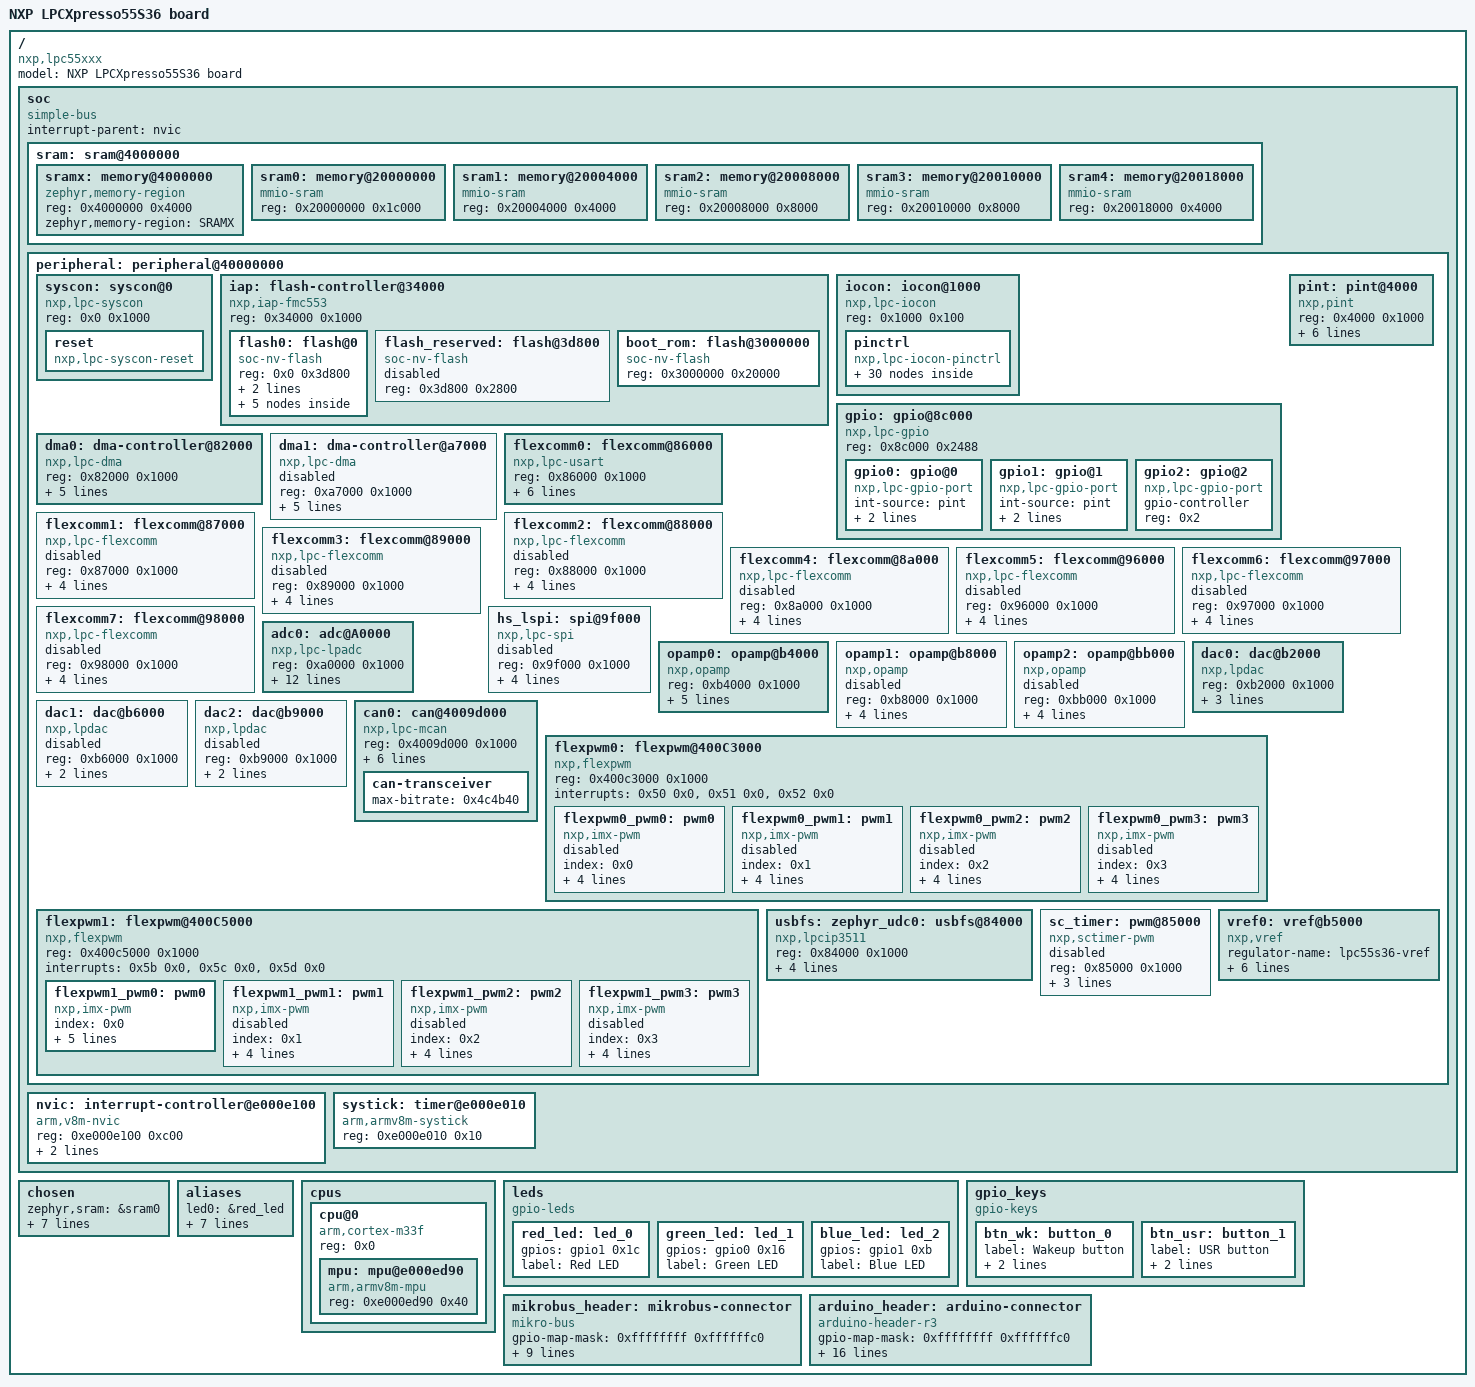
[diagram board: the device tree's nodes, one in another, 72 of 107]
/dts-v1/;

/* node '/' defined in zephyr/dts/arm/nxp/nxp_lpc55S36_ns.dtsi:7 */
/ {
	#address-cells = < 0x1 >;            /* in zephyr/dts/common/skeleton.dtsi:10 */
	#size-cells = < 0x1 >;               /* in zephyr/dts/common/skeleton.dtsi:11 */
	model = "NXP LPCXpresso55S36 board"; /* in zephyr/boards/nxp/lpcxpresso55s36/lpcxpresso55s36.dts:15 */
	compatible = "nxp,lpc55xxx",
	             "nxp,lpc";              /* in zephyr/boards/nxp/lpcxpresso55s36/lpcxpresso55s36.dts:16 */

	/* node '/soc' defined in zephyr/dts/arm/nxp/nxp_lpc55S36_ns.dtsi:8 */
	soc {
		#address-cells = < 0x1 >;     /* in zephyr/dts/arm/armv8-m.dtsi:7 */
		#size-cells = < 0x1 >;        /* in zephyr/dts/arm/armv8-m.dtsi:8 */
		compatible = "simple-bus";    /* in zephyr/dts/arm/armv8-m.dtsi:9 */
		interrupt-parent = < &nvic >; /* in zephyr/dts/arm/armv8-m.dtsi:10 */
		ranges;                       /* in zephyr/dts/arm/armv8-m.dtsi:11 */

		/* node '/soc/sram@4000000' defined in zephyr/dts/arm/nxp/nxp_lpc55S36_ns.dtsi:9 */
		sram: sram@4000000 {
			ranges = < 0x4000000 0x4000000 0x20000000 >; /* in zephyr/dts/arm/nxp/nxp_lpc55S36_ns.dtsi:10 */
			#address-cells = < 0x1 >;                    /* in zephyr/dts/arm/nxp/nxp_lpc55S3x_common.dtsi:37 */
			#size-cells = < 0x1 >;                       /* in zephyr/dts/arm/nxp/nxp_lpc55S3x_common.dtsi:38 */

			/* node '/soc/sram@4000000/memory@4000000' defined in zephyr/dts/arm/nxp/nxp_lpc55S3x_common.dtsi:44 */
			sramx: memory@4000000 {
				compatible = "zephyr,memory-region",
				             "mmio-sram";            /* in zephyr/dts/arm/nxp/nxp_lpc55S3x_common.dtsi:45 */
				reg = < 0x4000000 0x4000 >;          /* in zephyr/dts/arm/nxp/nxp_lpc55S3x_common.dtsi:46 */
				zephyr,memory-region = "SRAMX";      /* in zephyr/dts/arm/nxp/nxp_lpc55S3x_common.dtsi:47 */
			};

			/* node '/soc/sram@4000000/memory@20000000' defined in zephyr/dts/arm/nxp/nxp_lpc55S3x_common.dtsi:50 */
			sram0: memory@20000000 {
				compatible = "mmio-sram";     /* in zephyr/dts/arm/nxp/nxp_lpc55S36_ns.dtsi:26 */
				reg = < 0x20000000 0x1c000 >; /* in zephyr/dts/arm/nxp/nxp_lpc55S36_ns.dtsi:27 */
			};

			/* node '/soc/sram@4000000/memory@20004000' defined in zephyr/dts/arm/nxp/nxp_lpc55S3x_common.dtsi:55 */
			sram1: memory@20004000 {
				compatible = "mmio-sram";    /* in zephyr/dts/arm/nxp/nxp_lpc55S3x_common.dtsi:56 */
				reg = < 0x20004000 0x4000 >; /* in zephyr/dts/arm/nxp/nxp_lpc55S3x_common.dtsi:57 */
			};

			/* node '/soc/sram@4000000/memory@20008000' defined in zephyr/dts/arm/nxp/nxp_lpc55S3x_common.dtsi:60 */
			sram2: memory@20008000 {
				compatible = "mmio-sram";    /* in zephyr/dts/arm/nxp/nxp_lpc55S3x_common.dtsi:61 */
				reg = < 0x20008000 0x8000 >; /* in zephyr/dts/arm/nxp/nxp_lpc55S3x_common.dtsi:62 */
			};

			/* node '/soc/sram@4000000/memory@20010000' defined in zephyr/dts/arm/nxp/nxp_lpc55S3x_common.dtsi:65 */
			sram3: memory@20010000 {
				compatible = "mmio-sram";    /* in zephyr/dts/arm/nxp/nxp_lpc55S3x_common.dtsi:66 */
				reg = < 0x20010000 0x8000 >; /* in zephyr/dts/arm/nxp/nxp_lpc55S3x_common.dtsi:67 */
			};

			/* node '/soc/sram@4000000/memory@20018000' defined in zephyr/dts/arm/nxp/nxp_lpc55S3x_common.dtsi:70 */
			sram4: memory@20018000 {
				compatible = "mmio-sram";    /* in zephyr/dts/arm/nxp/nxp_lpc55S3x_common.dtsi:71 */
				reg = < 0x20018000 0x4000 >; /* in zephyr/dts/arm/nxp/nxp_lpc55S3x_common.dtsi:72 */
			};
		};

		/* node '/soc/peripheral@40000000' defined in zephyr/dts/arm/nxp/nxp_lpc55S36_ns.dtsi:13 */
		peripheral: peripheral@40000000 {
			ranges = < 0x0 0x40000000 0x10000000 >; /* in zephyr/dts/arm/nxp/nxp_lpc55S36_ns.dtsi:14 */
			#address-cells = < 0x1 >;               /* in zephyr/dts/arm/nxp/nxp_lpc55S3x_common.dtsi:77 */
			#size-cells = < 0x1 >;                  /* in zephyr/dts/arm/nxp/nxp_lpc55S3x_common.dtsi:78 */

			/* node '/soc/peripheral@40000000/syscon@0' defined in zephyr/dts/arm/nxp/nxp_lpc55S3x_common.dtsi:80 */
			syscon: syscon@0 {
				compatible = "nxp,lpc-syscon"; /* in zephyr/dts/arm/nxp/nxp_lpc55S3x_common.dtsi:81 */
				reg = < 0x0 0x1000 >;          /* in zephyr/dts/arm/nxp/nxp_lpc55S3x_common.dtsi:82 */
				#clock-cells = < 0x1 >;        /* in zephyr/dts/arm/nxp/nxp_lpc55S3x_common.dtsi:83 */
				phandle = < 0x2 >;             /* in zephyr/dts/arm/nxp/nxp_lpc55S3x_common.dtsi:199 */

				/* node '/soc/peripheral@40000000/syscon@0/reset' defined in zephyr/dts/arm/nxp/nxp_lpc55S3x_common.dtsi:85 */
				reset: reset {
					compatible = "nxp,lpc-syscon-reset"; /* in zephyr/dts/arm/nxp/nxp_lpc55S3x_common.dtsi:86 */
					#reset-cells = < 0x1 >;              /* in zephyr/dts/arm/nxp/nxp_lpc55S3x_common.dtsi:87 */
					phandle = < 0x3 >;                   /* in zephyr/dts/arm/nxp/nxp_lpc55S3x_common.dtsi:200 */
				};
			};

			/* node '/soc/peripheral@40000000/flash-controller@34000' defined in zephyr/dts/arm/nxp/nxp_lpc55S3x_common.dtsi:91 */
			iap: flash-controller@34000 {
				compatible = "nxp,iap-fmc553"; /* in zephyr/dts/arm/nxp/nxp_lpc55S3x_common.dtsi:92 */
				reg = < 0x34000 0x1000 >;      /* in zephyr/dts/arm/nxp/nxp_lpc55S3x_common.dtsi:93 */
				#address-cells = < 0x1 >;      /* in zephyr/dts/arm/nxp/nxp_lpc55S3x_common.dtsi:94 */
				#size-cells = < 0x1 >;         /* in zephyr/dts/arm/nxp/nxp_lpc55S3x_common.dtsi:95 */
				status = "okay";               /* in zephyr/dts/arm/nxp/nxp_lpc55S3x_common.dtsi:96 */

				/* node '/soc/peripheral@40000000/flash-controller@34000/flash@0' defined in zephyr/dts/arm/nxp/nxp_lpc55S3x_common.dtsi:98 */
				flash0: flash@0 {
					compatible = "soc-nv-flash";  /* in zephyr/dts/arm/nxp/nxp_lpc55S3x_common.dtsi:99 */
					reg = < 0x0 0x3d800 >;        /* in zephyr/dts/arm/nxp/nxp_lpc55S3x_common.dtsi:100 */
					erase-block-size = < 0x200 >; /* in zephyr/dts/arm/nxp/nxp_lpc55S3x_common.dtsi:101 */
					write-block-size = < 0x200 >; /* in zephyr/dts/arm/nxp/nxp_lpc55S3x_common.dtsi:102 */

					/* node '/soc/peripheral@40000000/flash-controller@34000/flash@0/partitions' defined in zephyr/boards/nxp/lpcxpresso55s36/lpcxpresso55s36.dts:157 */
					partitions {
						compatible = "fixed-partitions"; /* in zephyr/boards/nxp/lpcxpresso55s36/lpcxpresso55s36.dts:158 */
						#address-cells = < 0x1 >;        /* in zephyr/boards/nxp/lpcxpresso55s36/lpcxpresso55s36.dts:159 */
						#size-cells = < 0x1 >;           /* in zephyr/boards/nxp/lpcxpresso55s36/lpcxpresso55s36.dts:160 */

						/* node '/soc/peripheral@40000000/flash-controller@34000/flash@0/partitions/partition@0' defined in zephyr/boards/nxp/lpcxpresso55s36/lpcxpresso55s36.dts:162 */
						boot_partition: partition@0 {
							label = "mcuboot";    /* in zephyr/boards/nxp/lpcxpresso55s36/lpcxpresso55s36.dts:163 */
							reg = < 0x0 0x8000 >; /* in zephyr/boards/nxp/lpcxpresso55s36/lpcxpresso55s36.dts:164 */
						};

						/* node '/soc/peripheral@40000000/flash-controller@34000/flash@0/partitions/partition@8000' defined in zephyr/boards/nxp/lpcxpresso55s36/lpcxpresso55s36.dts:167 */
						slot0_partition: partition@8000 {
							label = "image-0";        /* in zephyr/boards/nxp/lpcxpresso55s36/lpcxpresso55s36.dts:168 */
							reg = < 0x8000 0x18000 >; /* in zephyr/boards/nxp/lpcxpresso55s36/lpcxpresso55s36.dts:169 */
						};

						/* node '/soc/peripheral@40000000/flash-controller@34000/flash@0/partitions/partition@20000' defined in zephyr/boards/nxp/lpcxpresso55s36/lpcxpresso55s36.dts:172 */
						slot1_partition: partition@20000 {
							label = "image-1";         /* in zephyr/boards/nxp/lpcxpresso55s36/lpcxpresso55s36.dts:173 */
							reg = < 0x20000 0x18000 >; /* in zephyr/boards/nxp/lpcxpresso55s36/lpcxpresso55s36.dts:174 */
						};

						/* node '/soc/peripheral@40000000/flash-controller@34000/flash@0/partitions/partition@38000' defined in zephyr/boards/nxp/lpcxpresso55s36/lpcxpresso55s36.dts:177 */
						storage_partition: partition@38000 {
							label = "storage";        /* in zephyr/boards/nxp/lpcxpresso55s36/lpcxpresso55s36.dts:178 */
							reg = < 0x38000 0x5000 >; /* in zephyr/boards/nxp/lpcxpresso55s36/lpcxpresso55s36.dts:179 */
						};
					};
				};

				/* node '/soc/peripheral@40000000/flash-controller@34000/flash@3d800' defined in zephyr/dts/arm/nxp/nxp_lpc55S3x_common.dtsi:105 */
				flash_reserved: flash@3d800 {
					compatible = "soc-nv-flash"; /* in zephyr/dts/arm/nxp/nxp_lpc55S3x_common.dtsi:106 */
					reg = < 0x3d800 0x2800 >;    /* in zephyr/dts/arm/nxp/nxp_lpc55S3x_common.dtsi:107 */
					status = "disabled";         /* in zephyr/dts/arm/nxp/nxp_lpc55S3x_common.dtsi:108 */
				};

				/* node '/soc/peripheral@40000000/flash-controller@34000/flash@3000000' defined in zephyr/dts/arm/nxp/nxp_lpc55S3x_common.dtsi:111 */
				boot_rom: flash@3000000 {
					compatible = "soc-nv-flash"; /* in zephyr/dts/arm/nxp/nxp_lpc55S3x_common.dtsi:112 */
					reg = < 0x3000000 0x20000 >; /* in zephyr/dts/arm/nxp/nxp_lpc55S3x_common.dtsi:113 */
				};
			};

			/* node '/soc/peripheral@40000000/iocon@1000' defined in zephyr/dts/arm/nxp/nxp_lpc55S3x_common.dtsi:117 */
			iocon: iocon@1000 {
				compatible = "nxp,lpc-iocon";  /* in zephyr/dts/arm/nxp/nxp_lpc55S3x_common.dtsi:118 */
				reg = < 0x1000 0x100 >;        /* in zephyr/dts/arm/nxp/nxp_lpc55S3x_common.dtsi:119 */
				#address-cells = < 0x1 >;      /* in zephyr/dts/arm/nxp/nxp_lpc55S3x_common.dtsi:120 */
				#size-cells = < 0x1 >;         /* in zephyr/dts/arm/nxp/nxp_lpc55S3x_common.dtsi:121 */
				ranges = < 0x0 0x1000 0x100 >; /* in zephyr/dts/arm/nxp/nxp_lpc55S3x_common.dtsi:122 */

				/* node '/soc/peripheral@40000000/iocon@1000/pinctrl' defined in zephyr/dts/arm/nxp/nxp_lpc55S3x_common.dtsi:124 */
				pinctrl: pinctrl {
					compatible = "nxp,lpc-iocon-pinctrl"; /* in zephyr/dts/arm/nxp/nxp_lpc55S3x_common.dtsi:125 */

					/* node '/soc/peripheral@40000000/iocon@1000/pinctrl/pinmux_flexcomm0_usart' defined in zephyr/boards/nxp/lpcxpresso55s36/lpcxpresso55s36-pinctrl.dtsi:13 */
					pinmux_flexcomm0_usart: pinmux_flexcomm0_usart {
						phandle = < 0x5 >; /* in zephyr/boards/nxp/lpcxpresso55s36/lpcxpresso55s36.dts:132 */

						/* node '/soc/peripheral@40000000/iocon@1000/pinctrl/pinmux_flexcomm0_usart/group0' defined in zephyr/boards/nxp/lpcxpresso55s36/lpcxpresso55s36-pinctrl.dtsi:14 */
						group0 {
							pinmux = < 0x1d00001 >,
							         < 0x1e00001 >; /* in zephyr/boards/nxp/lpcxpresso55s36/lpcxpresso55s36-pinctrl.dtsi:15 */
							slew-rate = "standard"; /* in zephyr/boards/nxp/lpcxpresso55s36/lpcxpresso55s36-pinctrl.dtsi:17 */
						};
					};

					/* node '/soc/peripheral@40000000/iocon@1000/pinctrl/pinmux_flexcomm2_i2c' defined in zephyr/boards/nxp/lpcxpresso55s36/lpcxpresso55s36-pinctrl.dtsi:22 */
					pinmux_flexcomm2_i2c: pinmux_flexcomm2_i2c {

						/* node '/soc/peripheral@40000000/iocon@1000/pinctrl/pinmux_flexcomm2_i2c/group0' defined in zephyr/boards/nxp/lpcxpresso55s36/lpcxpresso55s36-pinctrl.dtsi:23 */
						group0 {
							pinmux = < 0x3a00001 >,
							         < 0x3900001 >; /* in zephyr/boards/nxp/lpcxpresso55s36/lpcxpresso55s36-pinctrl.dtsi:24 */
							slew-rate = "standard"; /* in zephyr/boards/nxp/lpcxpresso55s36/lpcxpresso55s36-pinctrl.dtsi:26 */
						};
					};

					/* node '/soc/peripheral@40000000/iocon@1000/pinctrl/pinmux_hs_lspi_default' defined in zephyr/boards/nxp/lpcxpresso55s36/lpcxpresso55s36-pinctrl.dtsi:31 */
					pinmux_hs_lspi_default: pinmux_hs_lspi_default {

						/* node '/soc/peripheral@40000000/iocon@1000/pinctrl/pinmux_hs_lspi_default/group0' defined in zephyr/boards/nxp/lpcxpresso55s36/lpcxpresso55s36-pinctrl.dtsi:32 */
						group0 {
							pinmux = < 0x2300006 >,
							         < 0x1a00009 >,
							         < 0x2200006 >,
							         < 0x1400008 >; /* in zephyr/boards/nxp/lpcxpresso55s36/lpcxpresso55s36-pinctrl.dtsi:33 */
							slew-rate = "standard"; /* in zephyr/boards/nxp/lpcxpresso55s36/lpcxpresso55s36-pinctrl.dtsi:37 */
						};
					};

					/* node '/soc/peripheral@40000000/iocon@1000/pinctrl/pinmux_lpadc0' defined in zephyr/boards/nxp/lpcxpresso55s36/lpcxpresso55s36-pinctrl.dtsi:41 */
					pinmux_lpadc0: pinmux_lpadc0 {
						phandle = < 0x7 >; /* in zephyr/boards/nxp/lpcxpresso55s36/lpcxpresso55s36.dts:148 */

						/* node '/soc/peripheral@40000000/iocon@1000/pinctrl/pinmux_lpadc0/group0' defined in zephyr/boards/nxp/lpcxpresso55s36/lpcxpresso55s36-pinctrl.dtsi:42 */
						group0 {
							pinmux = < 0x2980000 >; /* in zephyr/boards/nxp/lpcxpresso55s36/lpcxpresso55s36-pinctrl.dtsi:43 */
							slew-rate = "standard"; /* in zephyr/boards/nxp/lpcxpresso55s36/lpcxpresso55s36-pinctrl.dtsi:44 */
							nxp,analog-mode;        /* in zephyr/boards/nxp/lpcxpresso55s36/lpcxpresso55s36-pinctrl.dtsi:45 */
						};
					};

					/* node '/soc/peripheral@40000000/iocon@1000/pinctrl/pinmux_opamp0' defined in zephyr/boards/nxp/lpcxpresso55s36/lpcxpresso55s36-pinctrl.dtsi:49 */
					pinmux_opamp0: pinmux_opamp0 {
						phandle = < 0x8 >; /* in zephyr/boards/nxp/lpcxpresso55s36/lpcxpresso55s36.dts:214 */

						/* node '/soc/peripheral@40000000/iocon@1000/pinctrl/pinmux_opamp0/group0' defined in zephyr/boards/nxp/lpcxpresso55s36/lpcxpresso55s36-pinctrl.dtsi:50 */
						group0 {
							pinmux = < 0x800000 >,
							         < 0x2980000 >; /* in zephyr/boards/nxp/lpcxpresso55s36/lpcxpresso55s36-pinctrl.dtsi:51 */
							slew-rate = "standard"; /* in zephyr/boards/nxp/lpcxpresso55s36/lpcxpresso55s36-pinctrl.dtsi:53 */
							nxp,analog-mode;        /* in zephyr/boards/nxp/lpcxpresso55s36/lpcxpresso55s36-pinctrl.dtsi:54 */
						};
					};

					/* node '/soc/peripheral@40000000/iocon@1000/pinctrl/pinmux_sctimer_default' defined in zephyr/boards/nxp/lpcxpresso55s36/lpcxpresso55s36-pinctrl.dtsi:59 */
					pinmux_sctimer_default: pinmux_sctimer_default {

						/* node '/soc/peripheral@40000000/iocon@1000/pinctrl/pinmux_sctimer_default/group0' defined in zephyr/boards/nxp/lpcxpresso55s36/lpcxpresso55s36-pinctrl.dtsi:60 */
						group0 {
							pinmux = < 0x2400004 >,
							         < 0xf00004 >;  /* in zephyr/boards/nxp/lpcxpresso55s36/lpcxpresso55s36-pinctrl.dtsi:61 */
							slew-rate = "standard"; /* in zephyr/boards/nxp/lpcxpresso55s36/lpcxpresso55s36-pinctrl.dtsi:63 */
						};
					};

					/* node '/soc/peripheral@40000000/iocon@1000/pinctrl/pinmux_mcan_can0' defined in zephyr/boards/nxp/lpcxpresso55s36/lpcxpresso55s36-pinctrl.dtsi:68 */
					pinmux_mcan_can0: pinmux_mcan_can0 {
						phandle = < 0xa >; /* in zephyr/boards/nxp/lpcxpresso55s36/lpcxpresso55s36.dts:137 */

						/* node '/soc/peripheral@40000000/iocon@1000/pinctrl/pinmux_mcan_can0/group0' defined in zephyr/boards/nxp/lpcxpresso55s36/lpcxpresso55s36-pinctrl.dtsi:69 */
						group0 {
							pinmux = < 0x2300001 >,
							         < 0x2200001 >; /* in zephyr/boards/nxp/lpcxpresso55s36/lpcxpresso55s36-pinctrl.dtsi:70 */
							slew-rate = "standard"; /* in zephyr/boards/nxp/lpcxpresso55s36/lpcxpresso55s36-pinctrl.dtsi:72 */
						};
					};

					/* node '/soc/peripheral@40000000/iocon@1000/pinctrl/pinmux_flexpwm0_pwm0' defined in zephyr/boards/nxp/lpcxpresso55s36/lpcxpresso55s36-pinctrl.dtsi:76 */
					pinmux_flexpwm0_pwm0: pinmux_flexpwm0_pwm0 {

						/* node '/soc/peripheral@40000000/iocon@1000/pinctrl/pinmux_flexpwm0_pwm0/group0' defined in zephyr/boards/nxp/lpcxpresso55s36/lpcxpresso55s36-pinctrl.dtsi:77 */
						group0 {
							pinmux = < 0x348000b >,
							         < 0x310000b >; /* in zephyr/boards/nxp/lpcxpresso55s36/lpcxpresso55s36-pinctrl.dtsi:78 */
							slew-rate = "standard"; /* in zephyr/boards/nxp/lpcxpresso55s36/lpcxpresso55s36-pinctrl.dtsi:80 */
						};
					};

					/* node '/soc/peripheral@40000000/iocon@1000/pinctrl/pinmux_flexpwm0_pwm1' defined in zephyr/boards/nxp/lpcxpresso55s36/lpcxpresso55s36-pinctrl.dtsi:84 */
					pinmux_flexpwm0_pwm1: pinmux_flexpwm0_pwm1 {

						/* node '/soc/peripheral@40000000/iocon@1000/pinctrl/pinmux_flexpwm0_pwm1/group0' defined in zephyr/boards/nxp/lpcxpresso55s36/lpcxpresso55s36-pinctrl.dtsi:85 */
						group0 {
							pinmux = < 0x260000b >,
							         < 0x368000b >; /* in zephyr/boards/nxp/lpcxpresso55s36/lpcxpresso55s36-pinctrl.dtsi:86 */
							slew-rate = "standard"; /* in zephyr/boards/nxp/lpcxpresso55s36/lpcxpresso55s36-pinctrl.dtsi:88 */
						};
					};

					/* node '/soc/peripheral@40000000/iocon@1000/pinctrl/pinmux_flexpwm0_pwm2' defined in zephyr/boards/nxp/lpcxpresso55s36/lpcxpresso55s36-pinctrl.dtsi:92 */
					pinmux_flexpwm0_pwm2: pinmux_flexpwm0_pwm2 {

						/* node '/soc/peripheral@40000000/iocon@1000/pinctrl/pinmux_flexpwm0_pwm2/group0' defined in zephyr/boards/nxp/lpcxpresso55s36/lpcxpresso55s36-pinctrl.dtsi:93 */
						group0 {
							pinmux = < 0x280000b >,
							         < 0x240000b >; /* in zephyr/boards/nxp/lpcxpresso55s36/lpcxpresso55s36-pinctrl.dtsi:94 */
							slew-rate = "standard"; /* in zephyr/boards/nxp/lpcxpresso55s36/lpcxpresso55s36-pinctrl.dtsi:96 */
						};
					};

					/* node '/soc/peripheral@40000000/iocon@1000/pinctrl/pinmux_flexpwm1_pwm0' defined in zephyr/boards/nxp/lpcxpresso55s36/lpcxpresso55s36-pinctrl.dtsi:100 */
					pinmux_flexpwm1_pwm0: pinmux_flexpwm1_pwm0 {
						phandle = < 0xb >; /* in zephyr/boards/nxp/lpcxpresso55s36/lpcxpresso55s36.dts:188 */

						/* node '/soc/peripheral@40000000/iocon@1000/pinctrl/pinmux_flexpwm1_pwm0/group0' defined in zephyr/boards/nxp/lpcxpresso55s36/lpcxpresso55s36-pinctrl.dtsi:101 */
						group0 {
							pinmux = < 0x350000b >,
							         < 0x30000b >;  /* in zephyr/boards/nxp/lpcxpresso55s36/lpcxpresso55s36-pinctrl.dtsi:102 */
							slew-rate = "standard"; /* in zephyr/boards/nxp/lpcxpresso55s36/lpcxpresso55s36-pinctrl.dtsi:104 */
						};
					};

					/* node '/soc/peripheral@40000000/iocon@1000/pinctrl/pinmux_flexpwm1_pwm1' defined in zephyr/boards/nxp/lpcxpresso55s36/lpcxpresso55s36-pinctrl.dtsi:108 */
					pinmux_flexpwm1_pwm1: pinmux_flexpwm1_pwm1 {

						/* node '/soc/peripheral@40000000/iocon@1000/pinctrl/pinmux_flexpwm1_pwm1/group0' defined in zephyr/boards/nxp/lpcxpresso55s36/lpcxpresso55s36-pinctrl.dtsi:109 */
						group0 {
							pinmux = < 0x378000b >,
							         < 0x150000b >; /* in zephyr/boards/nxp/lpcxpresso55s36/lpcxpresso55s36-pinctrl.dtsi:110 */
							slew-rate = "standard"; /* in zephyr/boards/nxp/lpcxpresso55s36/lpcxpresso55s36-pinctrl.dtsi:112 */
						};
					};

					/* node '/soc/peripheral@40000000/iocon@1000/pinctrl/pinmux_flexpwm1_pwm2' defined in zephyr/boards/nxp/lpcxpresso55s36/lpcxpresso55s36-pinctrl.dtsi:116 */
					pinmux_flexpwm1_pwm2: pinmux_flexpwm1_pwm2 {

						/* node '/soc/peripheral@40000000/iocon@1000/pinctrl/pinmux_flexpwm1_pwm2/group0' defined in zephyr/boards/nxp/lpcxpresso55s36/lpcxpresso55s36-pinctrl.dtsi:117 */
						group0 {
							pinmux = < 0x390000b >,
							         < 0x3f0000b >; /* in zephyr/boards/nxp/lpcxpresso55s36/lpcxpresso55s36-pinctrl.dtsi:118 */
							slew-rate = "standard"; /* in zephyr/boards/nxp/lpcxpresso55s36/lpcxpresso55s36-pinctrl.dtsi:120 */
						};
					};

					/* node '/soc/peripheral@40000000/iocon@1000/pinctrl/pinmux_usbfs' defined in zephyr/boards/nxp/lpcxpresso55s36/lpcxpresso55s36-pinctrl.dtsi:124 */
					pinmux_usbfs: pinmux_usbfs {
						phandle = < 0xc >; /* in zephyr/boards/nxp/lpcxpresso55s36/lpcxpresso55s36.dts:194 */

						/* node '/soc/peripheral@40000000/iocon@1000/pinctrl/pinmux_usbfs/group0' defined in zephyr/boards/nxp/lpcxpresso55s36/lpcxpresso55s36-pinctrl.dtsi:125 */
						group0 {
							pinmux = < 0x3f00007 >; /* in zephyr/boards/nxp/lpcxpresso55s36/lpcxpresso55s36-pinctrl.dtsi:126 */
							slew-rate = "standard"; /* in zephyr/boards/nxp/lpcxpresso55s36/lpcxpresso55s36-pinctrl.dtsi:127 */
						};
					};

					/* node '/soc/peripheral@40000000/iocon@1000/pinctrl/pinmux_dac0' defined in zephyr/boards/nxp/lpcxpresso55s36/lpcxpresso55s36-pinctrl.dtsi:131 */
					pinmux_dac0: pinmux_dac0 {
						phandle = < 0x9 >; /* in zephyr/boards/nxp/lpcxpresso55s36/lpcxpresso55s36.dts:208 */

						/* node '/soc/peripheral@40000000/iocon@1000/pinctrl/pinmux_dac0/group0' defined in zephyr/boards/nxp/lpcxpresso55s36/lpcxpresso55s36-pinctrl.dtsi:132 */
						group0 {
							pinmux = < 0x3680000 >; /* in zephyr/boards/nxp/lpcxpresso55s36/lpcxpresso55s36-pinctrl.dtsi:133 */
							slew-rate = "standard"; /* in zephyr/boards/nxp/lpcxpresso55s36/lpcxpresso55s36-pinctrl.dtsi:134 */
							nxp,analog-mode;        /* in zephyr/boards/nxp/lpcxpresso55s36/lpcxpresso55s36-pinctrl.dtsi:135 */
						};
					};
				};
			};

			/* node '/soc/peripheral@40000000/gpio@8c000' defined in zephyr/dts/arm/nxp/nxp_lpc55S3x_common.dtsi:129 */
			gpio: gpio@8c000 {
				compatible = "nxp,lpc-gpio"; /* in zephyr/dts/arm/nxp/nxp_lpc55S3x_common.dtsi:130 */
				reg = < 0x8c000 0x2488 >;    /* in zephyr/dts/arm/nxp/nxp_lpc55S3x_common.dtsi:131 */
				#address-cells = < 0x1 >;    /* in zephyr/dts/arm/nxp/nxp_lpc55S3x_common.dtsi:132 */
				#size-cells = < 0x0 >;       /* in zephyr/dts/arm/nxp/nxp_lpc55S3x_common.dtsi:133 */

				/* node '/soc/peripheral@40000000/gpio@8c000/gpio@0' defined in zephyr/dts/arm/nxp/nxp_lpc55S3x_common.dtsi:135 */
				gpio0: gpio@0 {
					compatible = "nxp,lpc-gpio-port"; /* in zephyr/dts/arm/nxp/nxp_lpc55S3x_common.dtsi:136 */
					int-source = "pint";              /* in zephyr/dts/arm/nxp/nxp_lpc55S3x_common.dtsi:137 */
					gpio-controller;                  /* in zephyr/dts/arm/nxp/nxp_lpc55S3x_common.dtsi:138 */
					#gpio-cells = < 0x2 >;            /* in zephyr/dts/arm/nxp/nxp_lpc55S3x_common.dtsi:139 */
					reg = < 0x0 >;                    /* in zephyr/dts/arm/nxp/nxp_lpc55S3x_common.dtsi:140 */
					phandle = < 0xe >;                /* in zephyr/boards/nxp/lpcxpresso55s36/lpcxpresso55s36.dts:49 */
				};

				/* node '/soc/peripheral@40000000/gpio@8c000/gpio@1' defined in zephyr/dts/arm/nxp/nxp_lpc55S3x_common.dtsi:143 */
				gpio1: gpio@1 {
					compatible = "nxp,lpc-gpio-port"; /* in zephyr/dts/arm/nxp/nxp_lpc55S3x_common.dtsi:144 */
					int-source = "pint";              /* in zephyr/dts/arm/nxp/nxp_lpc55S3x_common.dtsi:145 */
					gpio-controller;                  /* in zephyr/dts/arm/nxp/nxp_lpc55S3x_common.dtsi:146 */
					#gpio-cells = < 0x2 >;            /* in zephyr/dts/arm/nxp/nxp_lpc55S3x_common.dtsi:147 */
					reg = < 0x1 >;                    /* in zephyr/dts/arm/nxp/nxp_lpc55S3x_common.dtsi:148 */
					phandle = < 0xd >;                /* in zephyr/boards/nxp/lpcxpresso55s36/lpcxpresso55s36.dts:44 */
				};

				/* node '/soc/peripheral@40000000/gpio@8c000/gpio@2' defined in zephyr/dts/arm/nxp/nxp_lpc55S3x_common.dtsi:151 */
				gpio2: gpio@2 {
					compatible = "nxp,lpc-gpio-port"; /* in zephyr/dts/arm/nxp/nxp_lpc55S3x_common.dtsi:152 */
					gpio-controller;                  /* in zephyr/dts/arm/nxp/nxp_lpc55S3x_common.dtsi:153 */
					#gpio-cells = < 0x2 >;            /* in zephyr/dts/arm/nxp/nxp_lpc55S3x_common.dtsi:154 */
					reg = < 0x2 >;                    /* in zephyr/dts/arm/nxp/nxp_lpc55S3x_common.dtsi:155 */
					phandle = < 0xf >;                /* in zephyr/boards/nxp/lpcxpresso55s36/lpcxpresso55s36.dts:103 */
				};
			};

			/* node '/soc/peripheral@40000000/dma-controller@82000' defined in zephyr/dts/arm/nxp/nxp_lpc55S3x_common.dtsi:159 */
			dma0: dma-controller@82000 {
				compatible = "nxp,lpc-dma";                  /* in zephyr/dts/arm/nxp/nxp_lpc55S3x_common.dtsi:160 */
				reg = < 0x82000 0x1000 >;                    /* in zephyr/dts/arm/nxp/nxp_lpc55S3x_common.dtsi:161 */
				interrupts = < 0x1 0x0 >;                    /* in zephyr/dts/arm/nxp/nxp_lpc55S3x_common.dtsi:162 */
				dma-channels = < 0x34 >;                     /* in zephyr/dts/arm/nxp/nxp_lpc55S3x_common.dtsi:163 */
				nxp,dma-num-of-otrigs = < 0x4 >;             /* in zephyr/dts/arm/nxp/nxp_lpc55S3x_common.dtsi:164 */
				nxp,dma-otrig-base-address = < 0x16000000 >; /* in zephyr/dts/arm/nxp/nxp_lpc55S3x_common.dtsi:165 */
				nxp,dma-itrig-base-address = < 0xe000011 >;  /* in zephyr/dts/arm/nxp/nxp_lpc55S3x_common.dtsi:166 */
				#dma-cells = < 0x1 >;                        /* in zephyr/dts/arm/nxp/nxp_lpc55S3x_common.dtsi:168 */
				status = "okay";                             /* in zephyr/boards/nxp/lpcxpresso55s36/lpcxpresso55s36.dts:199 */
				phandle = < 0x4 >;                           /* in zephyr/dts/arm/nxp/nxp_lpc55S3x_common.dtsi:201 */
			};

			/* node '/soc/peripheral@40000000/dma-controller@a7000' defined in zephyr/dts/arm/nxp/nxp_lpc55S3x_common.dtsi:171 */
			dma1: dma-controller@a7000 {
				compatible = "nxp,lpc-dma";                  /* in zephyr/dts/arm/nxp/nxp_lpc55S3x_common.dtsi:172 */
				reg = < 0xa7000 0x1000 >;                    /* in zephyr/dts/arm/nxp/nxp_lpc55S3x_common.dtsi:173 */
				interrupts = < 0x3a 0x0 >;                   /* in zephyr/dts/arm/nxp/nxp_lpc55S3x_common.dtsi:174 */
				dma-channels = < 0x10 >;                     /* in zephyr/dts/arm/nxp/nxp_lpc55S3x_common.dtsi:175 */
				nxp,dma-num-of-otrigs = < 0x4 >;             /* in zephyr/dts/arm/nxp/nxp_lpc55S3x_common.dtsi:176 */
				nxp,dma-otrig-base-address = < 0x24000002 >; /* in zephyr/dts/arm/nxp/nxp_lpc55S3x_common.dtsi:177 */
				nxp,dma-itrig-base-address = < 0x20000008 >; /* in zephyr/dts/arm/nxp/nxp_lpc55S3x_common.dtsi:178 */
				status = "disabled";                         /* in zephyr/dts/arm/nxp/nxp_lpc55S3x_common.dtsi:179 */
				#dma-cells = < 0x1 >;                        /* in zephyr/dts/arm/nxp/nxp_lpc55S3x_common.dtsi:180 */
			};

			/* node '/soc/peripheral@40000000/pint@4000' defined in zephyr/dts/arm/nxp/nxp_lpc55S3x_common.dtsi:183 */
			pint: pint@4000 {
				compatible = "nxp,pint";    /* in zephyr/dts/arm/nxp/nxp_lpc55S3x_common.dtsi:184 */
				reg = < 0x4000 0x1000 >;    /* in zephyr/dts/arm/nxp/nxp_lpc55S3x_common.dtsi:185 */
				interrupt-controller;       /* in zephyr/dts/arm/nxp/nxp_lpc55S3x_common.dtsi:186 */
				#interrupt-cells = < 0x1 >; /* in zephyr/dts/arm/nxp/nxp_lpc55S3x_common.dtsi:187 */
				#address-cells = < 0x0 >;   /* in zephyr/dts/arm/nxp/nxp_lpc55S3x_common.dtsi:188 */
				interrupts = < 0x4 0x2 >,
				             < 0x5 0x2 >,
				             < 0x6 0x2 >,
				             < 0x7 0x2 >,
				             < 0x20 0x2 >,
				             < 0x21 0x2 >,
				             < 0x22 0x2 >,
				             < 0x23 0x2 >;  /* in zephyr/dts/arm/nxp/nxp_lpc55S3x_common.dtsi:189 */
				num-lines = < 0x8 >;        /* in zephyr/dts/arm/nxp/nxp_lpc55S3x_common.dtsi:191 */
				num-inputs = < 0x40 >;      /* in zephyr/dts/arm/nxp/nxp_lpc55S3x_common.dtsi:192 */
			};

			/* node '/soc/peripheral@40000000/flexcomm@86000' defined in zephyr/dts/arm/nxp/nxp_lpc55S3x_common.dtsi:195 */
			flexcomm0: flexcomm@86000 {
				reg = < 0x86000 0x1000 >;                /* in zephyr/dts/arm/nxp/nxp_lpc55S3x_common.dtsi:197 */
				interrupts = < 0xe 0x0 >;                /* in zephyr/dts/arm/nxp/nxp_lpc55S3x_common.dtsi:198 */
				clocks = < &syscon 0x100 >;              /* in zephyr/dts/arm/nxp/nxp_lpc55S3x_common.dtsi:199 */
				resets = < &reset 0x1000b >;             /* in zephyr/dts/arm/nxp/nxp_lpc55S3x_common.dtsi:200 */
				dmas = < &dma0 0x4 >,
				       < &dma0 0x5 >;                    /* in zephyr/dts/arm/nxp/nxp_lpc55S3x_common.dtsi:201 */
				dma-names = "rx",
				            "tx";                        /* in zephyr/dts/arm/nxp/nxp_lpc55S3x_common.dtsi:202 */
				status = "okay";                         /* in zephyr/boards/nxp/lpcxpresso55s36/lpcxpresso55s36.dts:129 */
				compatible = "nxp,lpc-usart";            /* in zephyr/boards/nxp/lpcxpresso55s36/lpcxpresso55s36.dts:130 */
				current-speed = < 0x1c200 >;             /* in zephyr/boards/nxp/lpcxpresso55s36/lpcxpresso55s36.dts:131 */
				pinctrl-0 = < &pinmux_flexcomm0_usart >; /* in zephyr/boards/nxp/lpcxpresso55s36/lpcxpresso55s36.dts:132 */
				pinctrl-names = "default";               /* in zephyr/boards/nxp/lpcxpresso55s36/lpcxpresso55s36.dts:133 */
			};

			/* node '/soc/peripheral@40000000/flexcomm@87000' defined in zephyr/dts/arm/nxp/nxp_lpc55S3x_common.dtsi:206 */
			flexcomm1: flexcomm@87000 {
				compatible = "nxp,lpc-flexcomm"; /* in zephyr/dts/arm/nxp/nxp_lpc55S3x_common.dtsi:207 */
				reg = < 0x87000 0x1000 >;        /* in zephyr/dts/arm/nxp/nxp_lpc55S3x_common.dtsi:208 */
				interrupts = < 0xf 0x0 >;        /* in zephyr/dts/arm/nxp/nxp_lpc55S3x_common.dtsi:209 */
				clocks = < &syscon 0x101 >;      /* in zephyr/dts/arm/nxp/nxp_lpc55S3x_common.dtsi:210 */
				resets = < &reset 0x1000c >;     /* in zephyr/dts/arm/nxp/nxp_lpc55S3x_common.dtsi:211 */
				dmas = < &dma0 0x6 >,
				       < &dma0 0x7 >;            /* in zephyr/dts/arm/nxp/nxp_lpc55S3x_common.dtsi:212 */
				dma-names = "rx",
				            "tx";                /* in zephyr/dts/arm/nxp/nxp_lpc55S3x_common.dtsi:213 */
				status = "disabled";             /* in zephyr/dts/arm/nxp/nxp_lpc55S3x_common.dtsi:214 */
			};

			/* node '/soc/peripheral@40000000/flexcomm@88000' defined in zephyr/dts/arm/nxp/nxp_lpc55S3x_common.dtsi:217 */
			flexcomm2: flexcomm@88000 {
				compatible = "nxp,lpc-flexcomm"; /* in zephyr/dts/arm/nxp/nxp_lpc55S3x_common.dtsi:218 */
				reg = < 0x88000 0x1000 >;        /* in zephyr/dts/arm/nxp/nxp_lpc55S3x_common.dtsi:219 */
				interrupts = < 0x10 0x0 >;       /* in zephyr/dts/arm/nxp/nxp_lpc55S3x_common.dtsi:220 */
				clocks = < &syscon 0x102 >;      /* in zephyr/dts/arm/nxp/nxp_lpc55S3x_common.dtsi:221 */
				resets = < &reset 0x1000d >;     /* in zephyr/dts/arm/nxp/nxp_lpc55S3x_common.dtsi:222 */
				dmas = < &dma0 0xa >,
				       < &dma0 0xb >;            /* in zephyr/dts/arm/nxp/nxp_lpc55S3x_common.dtsi:223 */
				dma-names = "rx",
				            "tx";                /* in zephyr/dts/arm/nxp/nxp_lpc55S3x_common.dtsi:224 */
				status = "disabled";             /* in zephyr/dts/arm/nxp/nxp_lpc55S3x_common.dtsi:225 */
			};

			/* node '/soc/peripheral@40000000/flexcomm@89000' defined in zephyr/dts/arm/nxp/nxp_lpc55S3x_common.dtsi:228 */
			flexcomm3: flexcomm@89000 {
				compatible = "nxp,lpc-flexcomm"; /* in zephyr/dts/arm/nxp/nxp_lpc55S3x_common.dtsi:229 */
				reg = < 0x89000 0x1000 >;        /* in zephyr/dts/arm/nxp/nxp_lpc55S3x_common.dtsi:230 */
				interrupts = < 0x11 0x0 >;       /* in zephyr/dts/arm/nxp/nxp_lpc55S3x_common.dtsi:231 */
				clocks = < &syscon 0x103 >;      /* in zephyr/dts/arm/nxp/nxp_lpc55S3x_common.dtsi:232 */
				resets = < &reset 0x1000e >;     /* in zephyr/dts/arm/nxp/nxp_lpc55S3x_common.dtsi:233 */
				dmas = < &dma0 0x8 >,
				       < &dma0 0x9 >;            /* in zephyr/dts/arm/nxp/nxp_lpc55S3x_common.dtsi:234 */
				dma-names = "rx",
				            "tx";                /* in zephyr/dts/arm/nxp/nxp_lpc55S3x_common.dtsi:235 */
				status = "disabled";             /* in zephyr/dts/arm/nxp/nxp_lpc55S3x_common.dtsi:236 */
			};

			/* node '/soc/peripheral@40000000/flexcomm@8a000' defined in zephyr/dts/arm/nxp/nxp_lpc55S3x_common.dtsi:239 */
			flexcomm4: flexcomm@8a000 {
				compatible = "nxp,lpc-flexcomm"; /* in zephyr/dts/arm/nxp/nxp_lpc55S3x_common.dtsi:240 */
				reg = < 0x8a000 0x1000 >;        /* in zephyr/dts/arm/nxp/nxp_lpc55S3x_common.dtsi:241 */
				interrupts = < 0x12 0x0 >;       /* in zephyr/dts/arm/nxp/nxp_lpc55S3x_common.dtsi:242 */
				clocks = < &syscon 0x104 >;      /* in zephyr/dts/arm/nxp/nxp_lpc55S3x_common.dtsi:243 */
				resets = < &reset 0x1000f >;     /* in zephyr/dts/arm/nxp/nxp_lpc55S3x_common.dtsi:244 */
				dmas = < &dma0 0xc >,
				       < &dma0 0xd >;            /* in zephyr/dts/arm/nxp/nxp_lpc55S3x_common.dtsi:245 */
				dma-names = "rx",
				            "tx";                /* in zephyr/dts/arm/nxp/nxp_lpc55S3x_common.dtsi:246 */
				status = "disabled";             /* in zephyr/dts/arm/nxp/nxp_lpc55S3x_common.dtsi:247 */
			};

			/* node '/soc/peripheral@40000000/flexcomm@96000' defined in zephyr/dts/arm/nxp/nxp_lpc55S3x_common.dtsi:250 */
			flexcomm5: flexcomm@96000 {
				compatible = "nxp,lpc-flexcomm"; /* in zephyr/dts/arm/nxp/nxp_lpc55S3x_common.dtsi:251 */
				reg = < 0x96000 0x1000 >;        /* in zephyr/dts/arm/nxp/nxp_lpc55S3x_common.dtsi:252 */
				interrupts = < 0x13 0x0 >;       /* in zephyr/dts/arm/nxp/nxp_lpc55S3x_common.dtsi:253 */
				clocks = < &syscon 0x105 >;      /* in zephyr/dts/arm/nxp/nxp_lpc55S3x_common.dtsi:254 */
				resets = < &reset 0x10010 >;     /* in zephyr/dts/arm/nxp/nxp_lpc55S3x_common.dtsi:255 */
				dmas = < &dma0 0xe >,
				       < &dma0 0xf >;            /* in zephyr/dts/arm/nxp/nxp_lpc55S3x_common.dtsi:256 */
				dma-names = "rx",
				            "tx";                /* in zephyr/dts/arm/nxp/nxp_lpc55S3x_common.dtsi:257 */
				status = "disabled";             /* in zephyr/dts/arm/nxp/nxp_lpc55S3x_common.dtsi:258 */
			};

			/* node '/soc/peripheral@40000000/flexcomm@97000' defined in zephyr/dts/arm/nxp/nxp_lpc55S3x_common.dtsi:261 */
			flexcomm6: flexcomm@97000 {
				compatible = "nxp,lpc-flexcomm"; /* in zephyr/dts/arm/nxp/nxp_lpc55S3x_common.dtsi:262 */
				reg = < 0x97000 0x1000 >;        /* in zephyr/dts/arm/nxp/nxp_lpc55S3x_common.dtsi:263 */
				interrupts = < 0x14 0x0 >;       /* in zephyr/dts/arm/nxp/nxp_lpc55S3x_common.dtsi:264 */
				clocks = < &syscon 0x106 >;      /* in zephyr/dts/arm/nxp/nxp_lpc55S3x_common.dtsi:265 */
				resets = < &reset 0x10011 >;     /* in zephyr/dts/arm/nxp/nxp_lpc55S3x_common.dtsi:266 */
				dmas = < &dma0 0x10 >,
				       < &dma0 0x11 >;           /* in zephyr/dts/arm/nxp/nxp_lpc55S3x_common.dtsi:267 */
				dma-names = "rx",
				            "tx";                /* in zephyr/dts/arm/nxp/nxp_lpc55S3x_common.dtsi:268 */
				status = "disabled";             /* in zephyr/dts/arm/nxp/nxp_lpc55S3x_common.dtsi:269 */
			};

			/* node '/soc/peripheral@40000000/flexcomm@98000' defined in zephyr/dts/arm/nxp/nxp_lpc55S3x_common.dtsi:272 */
			flexcomm7: flexcomm@98000 {
				compatible = "nxp,lpc-flexcomm"; /* in zephyr/dts/arm/nxp/nxp_lpc55S3x_common.dtsi:273 */
				reg = < 0x98000 0x1000 >;        /* in zephyr/dts/arm/nxp/nxp_lpc55S3x_common.dtsi:274 */
				interrupts = < 0x15 0x0 >;       /* in zephyr/dts/arm/nxp/nxp_lpc55S3x_common.dtsi:275 */
				clocks = < &syscon 0x107 >;      /* in zephyr/dts/arm/nxp/nxp_lpc55S3x_common.dtsi:276 */
				resets = < &reset 0x10012 >;     /* in zephyr/dts/arm/nxp/nxp_lpc55S3x_common.dtsi:277 */
				dmas = < &dma0 0x12 >,
				       < &dma0 0x13 >;           /* in zephyr/dts/arm/nxp/nxp_lpc55S3x_common.dtsi:278 */
				dma-names = "rx",
				            "tx";                /* in zephyr/dts/arm/nxp/nxp_lpc55S3x_common.dtsi:279 */
				status = "disabled";             /* in zephyr/dts/arm/nxp/nxp_lpc55S3x_common.dtsi:280 */
			};

			/* node '/soc/peripheral@40000000/spi@9f000' defined in zephyr/dts/arm/nxp/nxp_lpc55S3x_common.dtsi:283 */
			hs_lspi: spi@9f000 {
				compatible = "nxp,lpc-spi";  /* in zephyr/dts/arm/nxp/nxp_lpc55S3x_common.dtsi:284 */
				reg = < 0x9f000 0x1000 >;    /* in zephyr/dts/arm/nxp/nxp_lpc55S3x_common.dtsi:285 */
				interrupts = < 0x3b 0x0 >;   /* in zephyr/dts/arm/nxp/nxp_lpc55S3x_common.dtsi:286 */
				clocks = < &syscon 0x10e >;  /* in zephyr/dts/arm/nxp/nxp_lpc55S3x_common.dtsi:287 */
				resets = < &reset 0x2001c >; /* in zephyr/dts/arm/nxp/nxp_lpc55S3x_common.dtsi:288 */
				dmas = < &dma0 0x2 >,
				       < &dma0 0x3 >;        /* in zephyr/dts/arm/nxp/nxp_lpc55S3x_common.dtsi:289 */
				dma-names = "rx",
				            "tx";            /* in zephyr/dts/arm/nxp/nxp_lpc55S3x_common.dtsi:290 */
				status = "disabled";         /* in zephyr/dts/arm/nxp/nxp_lpc55S3x_common.dtsi:291 */
				#address-cells = < 0x1 >;    /* in zephyr/dts/arm/nxp/nxp_lpc55S3x_common.dtsi:292 */
				#size-cells = < 0x0 >;       /* in zephyr/dts/arm/nxp/nxp_lpc55S3x_common.dtsi:293 */
			};

			/* node '/soc/peripheral@40000000/adc@A0000' defined in zephyr/dts/arm/nxp/nxp_lpc55S3x_common.dtsi:296 */
			adc0: adc@A0000 {
				compatible = "nxp,lpc-lpadc";      /* in zephyr/dts/arm/nxp/nxp_lpc55S3x_common.dtsi:297 */
				reg = < 0xa0000 0x1000 >;          /* in zephyr/dts/arm/nxp/nxp_lpc55S3x_common.dtsi:298 */
				interrupts = < 0x16 0x0 >;         /* in zephyr/dts/arm/nxp/nxp_lpc55S3x_common.dtsi:299 */
				clk-divider = < 0x8 >;             /* in zephyr/dts/arm/nxp/nxp_lpc55S3x_common.dtsi:301 */
				clk-source = < 0x0 >;              /* in zephyr/dts/arm/nxp/nxp_lpc55S3x_common.dtsi:302 */
				voltage-ref = < 0x1 >;             /* in zephyr/dts/arm/nxp/nxp_lpc55S3x_common.dtsi:303 */
				calibration-average = < 0x80 >;    /* in zephyr/dts/arm/nxp/nxp_lpc55S3x_common.dtsi:304 */
				power-level = < 0x0 >;             /* in zephyr/dts/arm/nxp/nxp_lpc55S3x_common.dtsi:305 */
				offset-value-a = < 0xa >;          /* in zephyr/dts/arm/nxp/nxp_lpc55S3x_common.dtsi:306 */
				offset-value-b = < 0xa >;          /* in zephyr/dts/arm/nxp/nxp_lpc55S3x_common.dtsi:307 */
				#io-channel-cells = < 0x1 >;       /* in zephyr/dts/arm/nxp/nxp_lpc55S3x_common.dtsi:308 */
				dmas = < &dma0 0x15 >,
				       < &dma0 0x16 >;             /* in zephyr/dts/arm/nxp/nxp_lpc55S3x_common.dtsi:309 */
				dma-names = "adc0-dma0",
				            "adc0-dma1";           /* in zephyr/dts/arm/nxp/nxp_lpc55S3x_common.dtsi:310 */
				nxp,references = < &vref0 0x708 >; /* in zephyr/dts/arm/nxp/nxp_lpc55S3x_common.dtsi:311 */
				clocks = < &syscon 0xf00 >;        /* in zephyr/dts/arm/nxp/nxp_lpc55S3x_common.dtsi:312 */
				status = "okay";                   /* in zephyr/boards/nxp/lpcxpresso55s36/lpcxpresso55s36.dts:147 */
				pinctrl-0 = < &pinmux_lpadc0 >;    /* in zephyr/boards/nxp/lpcxpresso55s36/lpcxpresso55s36.dts:148 */
				pinctrl-names = "default";         /* in zephyr/boards/nxp/lpcxpresso55s36/lpcxpresso55s36.dts:149 */
			};

			/* node '/soc/peripheral@40000000/opamp@b4000' defined in zephyr/dts/arm/nxp/nxp_lpc55S3x_common.dtsi:315 */
			opamp0: opamp@b4000 {
				compatible = "nxp,opamp";       /* in zephyr/dts/arm/nxp/nxp_lpc55S3x_common.dtsi:316 */
				reg = < 0xb4000 0x1000 >;       /* in zephyr/dts/arm/nxp/nxp_lpc55S3x_common.dtsi:317 */
				operation-mode = "low_noise";   /* in zephyr/dts/arm/nxp/nxp_lpc55S3x_common.dtsi:319 */
				functional-mode = "follower";   /* in zephyr/dts/arm/nxp/nxp_lpc55S3x_common.dtsi:320 */
				clocks = < &syscon 0x1800 >;    /* in zephyr/dts/arm/nxp/nxp_lpc55S3x_common.dtsi:321 */
				resets = < &reset 0x3000c >;    /* in zephyr/dts/arm/nxp/nxp_lpc55S3x_common.dtsi:322 */
				status = "okay";                /* in zephyr/boards/nxp/lpcxpresso55s36/lpcxpresso55s36.dts:213 */
				pinctrl-0 = < &pinmux_opamp0 >; /* in zephyr/boards/nxp/lpcxpresso55s36/lpcxpresso55s36.dts:214 */
				pinctrl-names = "default";      /* in zephyr/boards/nxp/lpcxpresso55s36/lpcxpresso55s36.dts:215 */
			};

			/* node '/soc/peripheral@40000000/opamp@b8000' defined in zephyr/dts/arm/nxp/nxp_lpc55S3x_common.dtsi:325 */
			opamp1: opamp@b8000 {
				compatible = "nxp,opamp";     /* in zephyr/dts/arm/nxp/nxp_lpc55S3x_common.dtsi:326 */
				reg = < 0xb8000 0x1000 >;     /* in zephyr/dts/arm/nxp/nxp_lpc55S3x_common.dtsi:327 */
				status = "disabled";          /* in zephyr/dts/arm/nxp/nxp_lpc55S3x_common.dtsi:328 */
				operation-mode = "low_noise"; /* in zephyr/dts/arm/nxp/nxp_lpc55S3x_common.dtsi:329 */
				functional-mode = "follower"; /* in zephyr/dts/arm/nxp/nxp_lpc55S3x_common.dtsi:330 */
				clocks = < &syscon 0x1801 >;  /* in zephyr/dts/arm/nxp/nxp_lpc55S3x_common.dtsi:331 */
				resets = < &reset 0x3000d >;  /* in zephyr/dts/arm/nxp/nxp_lpc55S3x_common.dtsi:332 */
			};

			/* node '/soc/peripheral@40000000/opamp@bb000' defined in zephyr/dts/arm/nxp/nxp_lpc55S3x_common.dtsi:335 */
			opamp2: opamp@bb000 {
				compatible = "nxp,opamp";     /* in zephyr/dts/arm/nxp/nxp_lpc55S3x_common.dtsi:336 */
				reg = < 0xbb000 0x1000 >;     /* in zephyr/dts/arm/nxp/nxp_lpc55S3x_common.dtsi:337 */
				status = "disabled";          /* in zephyr/dts/arm/nxp/nxp_lpc55S3x_common.dtsi:338 */
				operation-mode = "low_noise"; /* in zephyr/dts/arm/nxp/nxp_lpc55S3x_common.dtsi:339 */
				functional-mode = "follower"; /* in zephyr/dts/arm/nxp/nxp_lpc55S3x_common.dtsi:340 */
				clocks = < &syscon 0x1802 >;  /* in zephyr/dts/arm/nxp/nxp_lpc55S3x_common.dtsi:341 */
				resets = < &reset 0x3000e >;  /* in zephyr/dts/arm/nxp/nxp_lpc55S3x_common.dtsi:342 */
			};

			/* node '/soc/peripheral@40000000/dac@b2000' defined in zephyr/dts/arm/nxp/nxp_lpc55S3x_common.dtsi:345 */
			dac0: dac@b2000 {
				compatible = "nxp,lpdac";     /* in zephyr/dts/arm/nxp/nxp_lpc55S3x_common.dtsi:346 */
				reg = < 0xb2000 0x1000 >;     /* in zephyr/dts/arm/nxp/nxp_lpc55S3x_common.dtsi:347 */
				interrupts = < 0x4a 0x0 >;    /* in zephyr/dts/arm/nxp/nxp_lpc55S3x_common.dtsi:348 */
				voltage-reference = < 0x0 >;  /* in zephyr/dts/arm/nxp/nxp_lpc55S3x_common.dtsi:350 */
				#io-channel-cells = < 0x1 >;  /* in zephyr/dts/arm/nxp/nxp_lpc55S3x_common.dtsi:351 */
				status = "okay";              /* in zephyr/boards/nxp/lpcxpresso55s36/lpcxpresso55s36.dts:207 */
				pinctrl-0 = < &pinmux_dac0 >; /* in zephyr/boards/nxp/lpcxpresso55s36/lpcxpresso55s36.dts:208 */
				pinctrl-names = "default";    /* in zephyr/boards/nxp/lpcxpresso55s36/lpcxpresso55s36.dts:209 */
			};

			/* node '/soc/peripheral@40000000/dac@b6000' defined in zephyr/dts/arm/nxp/nxp_lpc55S3x_common.dtsi:354 */
			dac1: dac@b6000 {
				compatible = "nxp,lpdac";    /* in zephyr/dts/arm/nxp/nxp_lpc55S3x_common.dtsi:355 */
				reg = < 0xb6000 0x1000 >;    /* in zephyr/dts/arm/nxp/nxp_lpc55S3x_common.dtsi:356 */
				interrupts = < 0x4b 0x0 >;   /* in zephyr/dts/arm/nxp/nxp_lpc55S3x_common.dtsi:357 */
				status = "disabled";         /* in zephyr/dts/arm/nxp/nxp_lpc55S3x_common.dtsi:358 */
				voltage-reference = < 0x0 >; /* in zephyr/dts/arm/nxp/nxp_lpc55S3x_common.dtsi:359 */
				#io-channel-cells = < 0x1 >; /* in zephyr/dts/arm/nxp/nxp_lpc55S3x_common.dtsi:360 */
			};

			/* node '/soc/peripheral@40000000/dac@b9000' defined in zephyr/dts/arm/nxp/nxp_lpc55S3x_common.dtsi:363 */
			dac2: dac@b9000 {
				compatible = "nxp,lpdac";    /* in zephyr/dts/arm/nxp/nxp_lpc55S3x_common.dtsi:364 */
				reg = < 0xb9000 0x1000 >;    /* in zephyr/dts/arm/nxp/nxp_lpc55S3x_common.dtsi:365 */
				interrupts = < 0x4c 0x0 >;   /* in zephyr/dts/arm/nxp/nxp_lpc55S3x_common.dtsi:366 */
				status = "disabled";         /* in zephyr/dts/arm/nxp/nxp_lpc55S3x_common.dtsi:367 */
				voltage-reference = < 0x0 >; /* in zephyr/dts/arm/nxp/nxp_lpc55S3x_common.dtsi:368 */
				#io-channel-cells = < 0x1 >; /* in zephyr/dts/arm/nxp/nxp_lpc55S3x_common.dtsi:369 */
			};

			/* node '/soc/peripheral@40000000/can@4009d000' defined in zephyr/dts/arm/nxp/nxp_lpc55S3x_common.dtsi:372 */
			can0: can@4009d000 {
				compatible = "nxp,lpc-mcan";                          /* in zephyr/dts/arm/nxp/nxp_lpc55S3x_common.dtsi:373 */
				reg = < 0x4009d000 0x1000 >;                          /* in zephyr/dts/arm/nxp/nxp_lpc55S3x_common.dtsi:374 */
				interrupts = < 0x2b 0x0 >,
				             < 0x2c 0x0 >;                            /* in zephyr/dts/arm/nxp/nxp_lpc55S3x_common.dtsi:375 */
				interrupt-names = "int0",
				                  "int1";                             /* in zephyr/dts/arm/nxp/nxp_lpc55S3x_common.dtsi:376 */
				clocks = < &syscon 0x300 >;                           /* in zephyr/dts/arm/nxp/nxp_lpc55S3x_common.dtsi:377 */
				resets = < &reset 0x10007 >;                          /* in zephyr/dts/arm/nxp/nxp_lpc55S3x_common.dtsi:378 */
				bosch,mram-cfg = < 0x0 0xf 0xf 0x8 0x8 0x0 0xf 0xf >; /* in zephyr/dts/arm/nxp/nxp_lpc55S3x_common.dtsi:379 */
				pinctrl-0 = < &pinmux_mcan_can0 >;                    /* in zephyr/boards/nxp/lpcxpresso55s36/lpcxpresso55s36.dts:137 */
				pinctrl-names = "default";                            /* in zephyr/boards/nxp/lpcxpresso55s36/lpcxpresso55s36.dts:138 */
				status = "okay";                                      /* in zephyr/boards/nxp/lpcxpresso55s36/lpcxpresso55s36.dts:139 */

				/* node '/soc/peripheral@40000000/can@4009d000/can-transceiver' defined in zephyr/boards/nxp/lpcxpresso55s36/lpcxpresso55s36.dts:141 */
				can-transceiver {
					max-bitrate = < 0x4c4b40 >; /* in zephyr/boards/nxp/lpcxpresso55s36/lpcxpresso55s36.dts:142 */
				};
			};

			/* node '/soc/peripheral@40000000/flexpwm@400C3000' defined in zephyr/dts/arm/nxp/nxp_lpc55S3x_common.dtsi:383 */
			flexpwm0: flexpwm@400C3000 {
				compatible = "nxp,flexpwm";        /* in zephyr/dts/arm/nxp/nxp_lpc55S3x_common.dtsi:384 */
				reg = < 0x400c3000 0x1000 >;       /* in zephyr/dts/arm/nxp/nxp_lpc55S3x_common.dtsi:385 */
				interrupt-names = "INPUT-CAPTURE",
				                  "FAULT",
				                  "RELOAD-ERROR";  /* in zephyr/dts/arm/nxp/nxp_lpc55S3x_common.dtsi:386 */
				interrupts = < 0x50 0x0 >,
				             < 0x51 0x0 >,
				             < 0x52 0x0 >;         /* in zephyr/dts/arm/nxp/nxp_lpc55S3x_common.dtsi:387 */

				/* node '/soc/peripheral@40000000/flexpwm@400C3000/pwm0' defined in zephyr/dts/arm/nxp/nxp_lpc55S3x_common.dtsi:389 */
				flexpwm0_pwm0: pwm0 {
					compatible = "nxp,imx-pwm";         /* in zephyr/dts/arm/nxp/nxp_lpc55S3x_common.dtsi:390 */
					index = < 0x0 >;                    /* in zephyr/dts/arm/nxp/nxp_lpc55S3x_common.dtsi:391 */
					interrupt-names = "COMPARE-SUB0",
					                  "RELOAD-SUB0";    /* in zephyr/dts/arm/nxp/nxp_lpc55S3x_common.dtsi:392 */
					interrupts = < 0x53 0x0 >,
					             < 0x54 0x0 >;          /* in zephyr/dts/arm/nxp/nxp_lpc55S3x_common.dtsi:393 */
					#pwm-cells = < 0x3 >;               /* in zephyr/dts/arm/nxp/nxp_lpc55S3x_common.dtsi:394 */
					clocks = < &syscon 0x400 0x0 0x0 >; /* in zephyr/dts/arm/nxp/nxp_lpc55S3x_common.dtsi:395 */
					nxp,prescaler = < 0x80 >;           /* in zephyr/dts/arm/nxp/nxp_lpc55S3x_common.dtsi:396 */
					status = "disabled";                /* in zephyr/dts/arm/nxp/nxp_lpc55S3x_common.dtsi:397 */
					run-in-wait;                        /* in zephyr/dts/arm/nxp/nxp_lpc55S3x_common.dtsi:398 */
				};

				/* node '/soc/peripheral@40000000/flexpwm@400C3000/pwm1' defined in zephyr/dts/arm/nxp/nxp_lpc55S3x_common.dtsi:401 */
				flexpwm0_pwm1: pwm1 {
					compatible = "nxp,imx-pwm";         /* in zephyr/dts/arm/nxp/nxp_lpc55S3x_common.dtsi:402 */
					index = < 0x1 >;                    /* in zephyr/dts/arm/nxp/nxp_lpc55S3x_common.dtsi:403 */
					interrupt-names = "COMPARE-SUB1",
					                  "RELOAD-SUB1";    /* in zephyr/dts/arm/nxp/nxp_lpc55S3x_common.dtsi:404 */
					interrupts = < 0x55 0x0 >,
					             < 0x56 0x0 >;          /* in zephyr/dts/arm/nxp/nxp_lpc55S3x_common.dtsi:405 */
					#pwm-cells = < 0x3 >;               /* in zephyr/dts/arm/nxp/nxp_lpc55S3x_common.dtsi:406 */
					clocks = < &syscon 0x400 0x0 0x0 >; /* in zephyr/dts/arm/nxp/nxp_lpc55S3x_common.dtsi:407 */
					nxp,prescaler = < 0x80 >;           /* in zephyr/dts/arm/nxp/nxp_lpc55S3x_common.dtsi:408 */
					status = "disabled";                /* in zephyr/dts/arm/nxp/nxp_lpc55S3x_common.dtsi:409 */
					run-in-wait;                        /* in zephyr/dts/arm/nxp/nxp_lpc55S3x_common.dtsi:410 */
				};

				/* node '/soc/peripheral@40000000/flexpwm@400C3000/pwm2' defined in zephyr/dts/arm/nxp/nxp_lpc55S3x_common.dtsi:413 */
				flexpwm0_pwm2: pwm2 {
					compatible = "nxp,imx-pwm";         /* in zephyr/dts/arm/nxp/nxp_lpc55S3x_common.dtsi:414 */
					index = < 0x2 >;                    /* in zephyr/dts/arm/nxp/nxp_lpc55S3x_common.dtsi:415 */
					interrupt-names = "COMPARE-SUB2",
					                  "RELOAD-SUB2";    /* in zephyr/dts/arm/nxp/nxp_lpc55S3x_common.dtsi:416 */
					interrupts = < 0x57 0x0 >,
					             < 0x58 0x0 >;          /* in zephyr/dts/arm/nxp/nxp_lpc55S3x_common.dtsi:417 */
					#pwm-cells = < 0x3 >;               /* in zephyr/dts/arm/nxp/nxp_lpc55S3x_common.dtsi:418 */
					clocks = < &syscon 0x400 0x0 0x0 >; /* in zephyr/dts/arm/nxp/nxp_lpc55S3x_common.dtsi:419 */
					nxp,prescaler = < 0x80 >;           /* in zephyr/dts/arm/nxp/nxp_lpc55S3x_common.dtsi:420 */
					status = "disabled";                /* in zephyr/dts/arm/nxp/nxp_lpc55S3x_common.dtsi:421 */
					run-in-wait;                        /* in zephyr/dts/arm/nxp/nxp_lpc55S3x_common.dtsi:422 */
				};

				/* node '/soc/peripheral@40000000/flexpwm@400C3000/pwm3' defined in zephyr/dts/arm/nxp/nxp_lpc55S3x_common.dtsi:425 */
				flexpwm0_pwm3: pwm3 {
					compatible = "nxp,imx-pwm";         /* in zephyr/dts/arm/nxp/nxp_lpc55S3x_common.dtsi:426 */
					index = < 0x3 >;                    /* in zephyr/dts/arm/nxp/nxp_lpc55S3x_common.dtsi:427 */
					interrupt-names = "COMPARE-SUB3",
					                  "RELOAD-SUB3";    /* in zephyr/dts/arm/nxp/nxp_lpc55S3x_common.dtsi:428 */
					interrupts = < 0x59 0x0 >,
					             < 0x5a 0x0 >;          /* in zephyr/dts/arm/nxp/nxp_lpc55S3x_common.dtsi:429 */
					#pwm-cells = < 0x3 >;               /* in zephyr/dts/arm/nxp/nxp_lpc55S3x_common.dtsi:430 */
					clocks = < &syscon 0x400 0x0 0x0 >; /* in zephyr/dts/arm/nxp/nxp_lpc55S3x_common.dtsi:431 */
					nxp,prescaler = < 0x80 >;           /* in zephyr/dts/arm/nxp/nxp_lpc55S3x_common.dtsi:432 */
					status = "disabled";                /* in zephyr/dts/arm/nxp/nxp_lpc55S3x_common.dtsi:433 */
					run-in-wait;                        /* in zephyr/dts/arm/nxp/nxp_lpc55S3x_common.dtsi:434 */
				};
			};

			/* node '/soc/peripheral@40000000/flexpwm@400C5000' defined in zephyr/dts/arm/nxp/nxp_lpc55S3x_common.dtsi:438 */
			flexpwm1: flexpwm@400C5000 {
				compatible = "nxp,flexpwm";        /* in zephyr/dts/arm/nxp/nxp_lpc55S3x_common.dtsi:439 */
				reg = < 0x400c5000 0x1000 >;       /* in zephyr/dts/arm/nxp/nxp_lpc55S3x_common.dtsi:440 */
				interrupt-names = "INPUT-CAPTURE",
				                  "FAULT",
				                  "RELOAD-ERROR";  /* in zephyr/dts/arm/nxp/nxp_lpc55S3x_common.dtsi:441 */
				interrupts = < 0x5b 0x0 >,
				             < 0x5c 0x0 >,
				             < 0x5d 0x0 >;         /* in zephyr/dts/arm/nxp/nxp_lpc55S3x_common.dtsi:442 */

				/* node '/soc/peripheral@40000000/flexpwm@400C5000/pwm0' defined in zephyr/dts/arm/nxp/nxp_lpc55S3x_common.dtsi:444 */
				flexpwm1_pwm0: pwm0 {
					compatible = "nxp,imx-pwm";            /* in zephyr/dts/arm/nxp/nxp_lpc55S3x_common.dtsi:445 */
					index = < 0x0 >;                       /* in zephyr/dts/arm/nxp/nxp_lpc55S3x_common.dtsi:446 */
					interrupt-names = "COMPARE-SUB0",
					                  "RELOAD-SUB0";       /* in zephyr/dts/arm/nxp/nxp_lpc55S3x_common.dtsi:447 */
					interrupts = < 0x5e 0x0 >,
					             < 0x5f 0x0 >;             /* in zephyr/dts/arm/nxp/nxp_lpc55S3x_common.dtsi:448 */
					#pwm-cells = < 0x3 >;                  /* in zephyr/dts/arm/nxp/nxp_lpc55S3x_common.dtsi:449 */
					clocks = < &syscon 0x400 0x0 0x0 >;    /* in zephyr/dts/arm/nxp/nxp_lpc55S3x_common.dtsi:450 */
					nxp,prescaler = < 0x80 >;              /* in zephyr/dts/arm/nxp/nxp_lpc55S3x_common.dtsi:451 */
					run-in-wait;                           /* in zephyr/dts/arm/nxp/nxp_lpc55S3x_common.dtsi:453 */
					status = "okay";                       /* in zephyr/boards/nxp/lpcxpresso55s36/lpcxpresso55s36.dts:187 */
					pinctrl-0 = < &pinmux_flexpwm1_pwm0 >; /* in zephyr/boards/nxp/lpcxpresso55s36/lpcxpresso55s36.dts:188 */
					pinctrl-names = "default";             /* in zephyr/boards/nxp/lpcxpresso55s36/lpcxpresso55s36.dts:189 */
				};

				/* node '/soc/peripheral@40000000/flexpwm@400C5000/pwm1' defined in zephyr/dts/arm/nxp/nxp_lpc55S3x_common.dtsi:456 */
				flexpwm1_pwm1: pwm1 {
					compatible = "nxp,imx-pwm";         /* in zephyr/dts/arm/nxp/nxp_lpc55S3x_common.dtsi:457 */
					index = < 0x1 >;                    /* in zephyr/dts/arm/nxp/nxp_lpc55S3x_common.dtsi:458 */
					interrupt-names = "COMPARE-SUB1",
					                  "RELOAD-SUB1";    /* in zephyr/dts/arm/nxp/nxp_lpc55S3x_common.dtsi:459 */
					interrupts = < 0x60 0x0 >,
					             < 0x61 0x0 >;          /* in zephyr/dts/arm/nxp/nxp_lpc55S3x_common.dtsi:460 */
					#pwm-cells = < 0x3 >;               /* in zephyr/dts/arm/nxp/nxp_lpc55S3x_common.dtsi:461 */
					clocks = < &syscon 0x400 0x0 0x0 >; /* in zephyr/dts/arm/nxp/nxp_lpc55S3x_common.dtsi:462 */
					nxp,prescaler = < 0x80 >;           /* in zephyr/dts/arm/nxp/nxp_lpc55S3x_common.dtsi:463 */
					status = "disabled";                /* in zephyr/dts/arm/nxp/nxp_lpc55S3x_common.dtsi:464 */
					run-in-wait;                        /* in zephyr/dts/arm/nxp/nxp_lpc55S3x_common.dtsi:465 */
				};

				/* node '/soc/peripheral@40000000/flexpwm@400C5000/pwm2' defined in zephyr/dts/arm/nxp/nxp_lpc55S3x_common.dtsi:468 */
				flexpwm1_pwm2: pwm2 {
					compatible = "nxp,imx-pwm";         /* in zephyr/dts/arm/nxp/nxp_lpc55S3x_common.dtsi:469 */
					index = < 0x2 >;                    /* in zephyr/dts/arm/nxp/nxp_lpc55S3x_common.dtsi:470 */
					interrupt-names = "COMPARE-SUB2",
					                  "RELOAD-SUB2";    /* in zephyr/dts/arm/nxp/nxp_lpc55S3x_common.dtsi:471 */
					interrupts = < 0x62 0x0 >,
					             < 0x63 0x0 >;          /* in zephyr/dts/arm/nxp/nxp_lpc55S3x_common.dtsi:472 */
					#pwm-cells = < 0x3 >;               /* in zephyr/dts/arm/nxp/nxp_lpc55S3x_common.dtsi:473 */
					clocks = < &syscon 0x400 0x0 0x0 >; /* in zephyr/dts/arm/nxp/nxp_lpc55S3x_common.dtsi:474 */
					nxp,prescaler = < 0x80 >;           /* in zephyr/dts/arm/nxp/nxp_lpc55S3x_common.dtsi:475 */
					status = "disabled";                /* in zephyr/dts/arm/nxp/nxp_lpc55S3x_common.dtsi:476 */
					run-in-wait;                        /* in zephyr/dts/arm/nxp/nxp_lpc55S3x_common.dtsi:477 */
				};

				/* node '/soc/peripheral@40000000/flexpwm@400C5000/pwm3' defined in zephyr/dts/arm/nxp/nxp_lpc55S3x_common.dtsi:480 */
				flexpwm1_pwm3: pwm3 {
					compatible = "nxp,imx-pwm";         /* in zephyr/dts/arm/nxp/nxp_lpc55S3x_common.dtsi:481 */
					index = < 0x3 >;                    /* in zephyr/dts/arm/nxp/nxp_lpc55S3x_common.dtsi:482 */
					interrupt-names = "COMPARE-SUB3",
					                  "RELOAD-SUB3";    /* in zephyr/dts/arm/nxp/nxp_lpc55S3x_common.dtsi:483 */
					interrupts = < 0x64 0x0 >,
					             < 0x65 0x0 >;          /* in zephyr/dts/arm/nxp/nxp_lpc55S3x_common.dtsi:484 */
					#pwm-cells = < 0x3 >;               /* in zephyr/dts/arm/nxp/nxp_lpc55S3x_common.dtsi:485 */
					clocks = < &syscon 0x400 0x0 0x0 >; /* in zephyr/dts/arm/nxp/nxp_lpc55S3x_common.dtsi:486 */
					nxp,prescaler = < 0x80 >;           /* in zephyr/dts/arm/nxp/nxp_lpc55S3x_common.dtsi:487 */
					status = "disabled";                /* in zephyr/dts/arm/nxp/nxp_lpc55S3x_common.dtsi:488 */
					run-in-wait;                        /* in zephyr/dts/arm/nxp/nxp_lpc55S3x_common.dtsi:489 */
				};
			};

			/* node '/soc/peripheral@40000000/usbfs@84000' defined in zephyr/dts/arm/nxp/nxp_lpc55S3x_common.dtsi:493 */
			usbfs: zephyr_udc0: usbfs@84000 {
				compatible = "nxp,lpcip3511";  /* in zephyr/dts/arm/nxp/nxp_lpc55S3x_common.dtsi:494 */
				reg = < 0x84000 0x1000 >;      /* in zephyr/dts/arm/nxp/nxp_lpc55S3x_common.dtsi:495 */
				interrupts = < 0x1c 0x0 >;     /* in zephyr/dts/arm/nxp/nxp_lpc55S3x_common.dtsi:496 */
				num-bidir-endpoints = < 0x5 >; /* in zephyr/dts/arm/nxp/nxp_lpc55S3x_common.dtsi:497 */
				maximum-speed = "full-speed";  /* in zephyr/dts/arm/nxp/nxp_lpc55S3x_common.dtsi:498 */
				status = "okay";               /* in zephyr/boards/nxp/lpcxpresso55s36/lpcxpresso55s36.dts:193 */
				pinctrl-0 = < &pinmux_usbfs >; /* in zephyr/boards/nxp/lpcxpresso55s36/lpcxpresso55s36.dts:194 */
				pinctrl-names = "default";     /* in zephyr/boards/nxp/lpcxpresso55s36/lpcxpresso55s36.dts:195 */
			};

			/* node '/soc/peripheral@40000000/pwm@85000' defined in zephyr/dts/arm/nxp/nxp_lpc55S3x_common.dtsi:502 */
			sc_timer: pwm@85000 {
				compatible = "nxp,sctimer-pwm";     /* in zephyr/dts/arm/nxp/nxp_lpc55S3x_common.dtsi:503 */
				reg = < 0x85000 0x1000 >;           /* in zephyr/dts/arm/nxp/nxp_lpc55S3x_common.dtsi:504 */
				interrupts = < 0xc 0x0 >;           /* in zephyr/dts/arm/nxp/nxp_lpc55S3x_common.dtsi:505 */
				status = "disabled";                /* in zephyr/dts/arm/nxp/nxp_lpc55S3x_common.dtsi:506 */
				clocks = < &syscon 0x900 0x0 0x0 >; /* in zephyr/dts/arm/nxp/nxp_lpc55S3x_common.dtsi:507 */
				prescaler = < 0x2 >;                /* in zephyr/dts/arm/nxp/nxp_lpc55S3x_common.dtsi:508 */
				#pwm-cells = < 0x3 >;               /* in zephyr/dts/arm/nxp/nxp_lpc55S3x_common.dtsi:509 */
			};

			/* node '/soc/peripheral@40000000/vref@b5000' defined in zephyr/dts/arm/nxp/nxp_lpc55S3x_common.dtsi:512 */
			vref0: vref@b5000 {
				compatible = "nxp,vref";                 /* in zephyr/dts/arm/nxp/nxp_lpc55S3x_common.dtsi:513 */
				regulator-name = "lpc55s36-vref";        /* in zephyr/dts/arm/nxp/nxp_lpc55S3x_common.dtsi:514 */
				reg = < 0xb5000 0x30 >;                  /* in zephyr/dts/arm/nxp/nxp_lpc55S3x_common.dtsi:515 */
				#nxp,reference-cells = < 0x1 >;          /* in zephyr/dts/arm/nxp/nxp_lpc55S3x_common.dtsi:517 */
				nxp,buffer-startup-delay-us = < 0x190 >; /* in zephyr/dts/arm/nxp/nxp_lpc55S3x_common.dtsi:518 */
				nxp,bandgap-startup-time-us = < 0x14 >;  /* in zephyr/dts/arm/nxp/nxp_lpc55S3x_common.dtsi:519 */
				nxp,current-compensation-en;             /* in zephyr/dts/arm/nxp/nxp_lpc55S3x_common.dtsi:520 */
				nxp,internal-voltage-regulator-en;       /* in zephyr/dts/arm/nxp/nxp_lpc55S3x_common.dtsi:521 */
				nxp,chop-oscillator-en;                  /* in zephyr/dts/arm/nxp/nxp_lpc55S3x_common.dtsi:522 */
				status = "okay";                         /* in zephyr/boards/nxp/lpcxpresso55s36/lpcxpresso55s36.dts:203 */
				phandle = < 0x6 >;                       /* in zephyr/dts/arm/nxp/nxp_lpc55S3x_common.dtsi:311 */
			};
		};

		/* node '/soc/interrupt-controller@e000e100' defined in zephyr/dts/arm/armv8-m.dtsi:13 */
		nvic: interrupt-controller@e000e100 {
			#address-cells = < 0x1 >;            /* in zephyr/dts/arm/armv8-m.dtsi:14 */
			compatible = "arm,v8m-nvic";         /* in zephyr/dts/arm/armv8-m.dtsi:15 */
			reg = < 0xe000e100 0xc00 >;          /* in zephyr/dts/arm/armv8-m.dtsi:16 */
			interrupt-controller;                /* in zephyr/dts/arm/armv8-m.dtsi:17 */
			#interrupt-cells = < 0x2 >;          /* in zephyr/dts/arm/armv8-m.dtsi:18 */
			arm,num-irq-priority-bits = < 0x3 >; /* in zephyr/dts/arm/nxp/nxp_lpc55S3x_common.dtsi:527 */
			phandle = < 0x1 >;                   /* in zephyr/dts/arm/armv8-m.dtsi:10 */
		};

		/* node '/soc/timer@e000e010' defined in zephyr/dts/arm/armv8-m.dtsi:21 */
		systick: timer@e000e010 {
			compatible = "arm,armv8m-systick"; /* in zephyr/dts/arm/armv8-m.dtsi:22 */
			reg = < 0xe000e010 0x10 >;         /* in zephyr/dts/arm/armv8-m.dtsi:23 */
		};
	};

	/* node '/chosen' defined in zephyr/dts/common/skeleton.dtsi:13 */
	chosen {
		zephyr,sram = &sram0;                     /* in zephyr/boards/nxp/lpcxpresso55s36/lpcxpresso55s36.dts:19 */
		zephyr,flash = &flash0;                   /* in zephyr/boards/nxp/lpcxpresso55s36/lpcxpresso55s36.dts:20 */
		zephyr,code-partition = &slot0_partition; /* in zephyr/boards/nxp/lpcxpresso55s36/lpcxpresso55s36.dts:21 */
		zephyr,uart-mcumgr = &flexcomm0;          /* in zephyr/boards/nxp/lpcxpresso55s36/lpcxpresso55s36.dts:22 */
		zephyr,console = &flexcomm0;              /* in zephyr/boards/nxp/lpcxpresso55s36/lpcxpresso55s36.dts:23 */
		zephyr,shell-uart = &flexcomm0;           /* in zephyr/boards/nxp/lpcxpresso55s36/lpcxpresso55s36.dts:24 */
		zephyr,canbus = &can0;                    /* in zephyr/boards/nxp/lpcxpresso55s36/lpcxpresso55s36.dts:25 */
		zephyr,flash-controller = &iap;           /* in zephyr/boards/nxp/lpcxpresso55s36/lpcxpresso55s36.dts:26 */
	};

	/* node '/aliases' defined in zephyr/dts/common/skeleton.dtsi:15 */
	aliases {
		led0 = &red_led;           /* in zephyr/boards/nxp/lpcxpresso55s36/lpcxpresso55s36.dts:30 */
		led1 = &green_led;         /* in zephyr/boards/nxp/lpcxpresso55s36/lpcxpresso55s36.dts:31 */
		led2 = &blue_led;          /* in zephyr/boards/nxp/lpcxpresso55s36/lpcxpresso55s36.dts:32 */
		sw0 = &btn_wk;             /* in zephyr/boards/nxp/lpcxpresso55s36/lpcxpresso55s36.dts:33 */
		sw1 = &btn_usr;            /* in zephyr/boards/nxp/lpcxpresso55s36/lpcxpresso55s36.dts:34 */
		usart-0 = &flexcomm0;      /* in zephyr/boards/nxp/lpcxpresso55s36/lpcxpresso55s36.dts:35 */
		pwm-0 = &flexpwm1_pwm0;    /* in zephyr/boards/nxp/lpcxpresso55s36/lpcxpresso55s36.dts:36 */
		mcuboot-button0 = &btn_wk; /* in zephyr/boards/nxp/lpcxpresso55s36/lpcxpresso55s36.dts:37 */
	};

	/* node '/cpus' defined in zephyr/dts/arm/nxp/nxp_lpc55S3x_common.dtsi:18 */
	cpus {
		#address-cells = < 0x1 >; /* in zephyr/dts/arm/nxp/nxp_lpc55S3x_common.dtsi:19 */
		#size-cells = < 0x0 >;    /* in zephyr/dts/arm/nxp/nxp_lpc55S3x_common.dtsi:20 */

		/* node '/cpus/cpu@0' defined in zephyr/dts/arm/nxp/nxp_lpc55S3x_common.dtsi:22 */
		cpu@0 {
			compatible = "arm,cortex-m33f"; /* in zephyr/dts/arm/nxp/nxp_lpc55S3x_common.dtsi:23 */
			reg = < 0x0 >;                  /* in zephyr/dts/arm/nxp/nxp_lpc55S3x_common.dtsi:24 */
			#address-cells = < 0x1 >;       /* in zephyr/dts/arm/nxp/nxp_lpc55S3x_common.dtsi:25 */
			#size-cells = < 0x1 >;          /* in zephyr/dts/arm/nxp/nxp_lpc55S3x_common.dtsi:26 */

			/* node '/cpus/cpu@0/mpu@e000ed90' defined in zephyr/dts/arm/nxp/nxp_lpc55S3x_common.dtsi:28 */
			mpu: mpu@e000ed90 {
				compatible = "arm,armv8m-mpu"; /* in zephyr/dts/arm/nxp/nxp_lpc55S3x_common.dtsi:29 */
				reg = < 0xe000ed90 0x40 >;     /* in zephyr/dts/arm/nxp/nxp_lpc55S3x_common.dtsi:30 */
			};
		};
	};

	/* node '/leds' defined in zephyr/boards/nxp/lpcxpresso55s36/lpcxpresso55s36.dts:40 */
	leds {
		compatible = "gpio-leds"; /* in zephyr/boards/nxp/lpcxpresso55s36/lpcxpresso55s36.dts:41 */

		/* node '/leds/led_0' defined in zephyr/boards/nxp/lpcxpresso55s36/lpcxpresso55s36.dts:43 */
		red_led: led_0 {
			gpios = < &gpio1 0x1c 0x0 >; /* in zephyr/boards/nxp/lpcxpresso55s36/lpcxpresso55s36.dts:44 */
			label = "Red LED";           /* in zephyr/boards/nxp/lpcxpresso55s36/lpcxpresso55s36.dts:45 */
		};

		/* node '/leds/led_1' defined in zephyr/boards/nxp/lpcxpresso55s36/lpcxpresso55s36.dts:48 */
		green_led: led_1 {
			gpios = < &gpio0 0x16 0x0 >; /* in zephyr/boards/nxp/lpcxpresso55s36/lpcxpresso55s36.dts:49 */
			label = "Green LED";         /* in zephyr/boards/nxp/lpcxpresso55s36/lpcxpresso55s36.dts:50 */
		};

		/* node '/leds/led_2' defined in zephyr/boards/nxp/lpcxpresso55s36/lpcxpresso55s36.dts:53 */
		blue_led: led_2 {
			gpios = < &gpio1 0xb 0x0 >; /* in zephyr/boards/nxp/lpcxpresso55s36/lpcxpresso55s36.dts:54 */
			label = "Blue LED";         /* in zephyr/boards/nxp/lpcxpresso55s36/lpcxpresso55s36.dts:55 */
		};
	};

	/* node '/gpio_keys' defined in zephyr/boards/nxp/lpcxpresso55s36/lpcxpresso55s36.dts:59 */
	gpio_keys {
		compatible = "gpio-keys"; /* in zephyr/boards/nxp/lpcxpresso55s36/lpcxpresso55s36.dts:60 */

		/* node '/gpio_keys/button_0' defined in zephyr/boards/nxp/lpcxpresso55s36/lpcxpresso55s36.dts:62 */
		btn_wk: button_0 {
			label = "Wakeup button";     /* in zephyr/boards/nxp/lpcxpresso55s36/lpcxpresso55s36.dts:63 */
			gpios = < &gpio1 0x12 0x1 >; /* in zephyr/boards/nxp/lpcxpresso55s36/lpcxpresso55s36.dts:64 */
			zephyr,code = < 0x8f >;      /* in zephyr/boards/nxp/lpcxpresso55s36/lpcxpresso55s36.dts:65 */
		};

		/* node '/gpio_keys/button_1' defined in zephyr/boards/nxp/lpcxpresso55s36/lpcxpresso55s36.dts:68 */
		btn_usr: button_1 {
			label = "USR button";        /* in zephyr/boards/nxp/lpcxpresso55s36/lpcxpresso55s36.dts:69 */
			gpios = < &gpio0 0x11 0x1 >; /* in zephyr/boards/nxp/lpcxpresso55s36/lpcxpresso55s36.dts:70 */
			zephyr,code = < 0xb >;       /* in zephyr/boards/nxp/lpcxpresso55s36/lpcxpresso55s36.dts:71 */
		};
	};

	/* node '/mikrobus-connector' defined in zephyr/boards/nxp/lpcxpresso55s36/lpcxpresso55s36.dts:75 */
	mikrobus_header: mikrobus-connector {
		compatible = "mikro-bus";                  /* in zephyr/boards/nxp/lpcxpresso55s36/lpcxpresso55s36.dts:76 */
		#gpio-cells = < 0x2 >;                     /* in zephyr/boards/nxp/lpcxpresso55s36/lpcxpresso55s36.dts:77 */
		gpio-map-mask = < 0xffffffff 0xffffffc0 >; /* in zephyr/boards/nxp/lpcxpresso55s36/lpcxpresso55s36.dts:78 */
		gpio-map-pass-thru = < 0x0 0x3f >;         /* in zephyr/boards/nxp/lpcxpresso55s36/lpcxpresso55s36.dts:79 */
		gpio-map = < 0x0 0x0 &gpio1 0x9 0x0 >,
		           < 0x2 0x0 &gpio0 0x14 0x0 >,
		           < 0x3 0x0 &gpio1 0x2 0x0 >,
		           < 0x4 0x0 &gpio1 0x3 0x0 >,
		           < 0x5 0x0 &gpio0 0x1a 0x0 >,
		           < 0x6 0x0 &gpio1 0x8 0x0 >,
		           < 0x7 0x0 &gpio0 0x11 0x0 >,
		           < 0x8 0x0 &gpio1 0x18 0x0 >,
		           < 0x9 0x0 &gpio1 0x19 0x0 >,
		           < 0xa 0x0 &gpio1 0x1e 0x0 >,
		           < 0xb 0x0 &gpio1 0x15 0x0 >;    /* in zephyr/boards/nxp/lpcxpresso55s36/lpcxpresso55s36.dts:80 */
	};

	/* node '/arduino-connector' defined in zephyr/boards/nxp/lpcxpresso55s36/lpcxpresso55s36.dts:98 */
	arduino_header: arduino-connector {
		compatible = "arduino-header-r3";          /* in zephyr/boards/nxp/lpcxpresso55s36/lpcxpresso55s36.dts:99 */
		#gpio-cells = < 0x2 >;                     /* in zephyr/boards/nxp/lpcxpresso55s36/lpcxpresso55s36.dts:100 */
		gpio-map-mask = < 0xffffffff 0xffffffc0 >; /* in zephyr/boards/nxp/lpcxpresso55s36/lpcxpresso55s36.dts:101 */
		gpio-map-pass-thru = < 0x0 0x3f >;         /* in zephyr/boards/nxp/lpcxpresso55s36/lpcxpresso55s36.dts:102 */
		gpio-map = < 0x0 0x0 &gpio0 0xf 0x0 >,
		           < 0x1 0x0 &gpio0 0x10 0x0 >,
		           < 0x2 0x0 &gpio0 0x0 0x0 >,
		           < 0x3 0x0 &gpio1 0xd 0x0 >,
		           < 0x4 0x0 &gpio1 0x15 0x0 >,
		           < 0x5 0x0 &gpio1 0x1e 0x0 >,
		           < 0x6 0x0 &gpio2 0x0 0x0 >,
		           < 0x7 0x0 &gpio2 0x1 0x0 >,
		           < 0x8 0x0 &gpio1 0x1a 0x0 >,
		           < 0x9 0x0 &gpio1 0x17 0x0 >,
		           < 0xa 0x0 &gpio1 0x8 0x0 >,
		           < 0xb 0x0 &gpio1 0x19 0x0 >,
		           < 0xc 0x0 &gpio1 0x0 0x0 >,
		           < 0xd 0x0 &gpio1 0x1c 0x0 >,
		           < 0xe 0x0 &gpio1 0x1b 0x0 >,
		           < 0xf 0x0 &gpio1 0x1d 0x0 >,
		           < 0x10 0x0 &gpio1 0x1a 0x0 >,
		           < 0x11 0x0 &gpio0 0x1a 0x0 >,
		           < 0x12 0x0 &gpio1 0x3 0x0 >,
		           < 0x13 0x0 &gpio1 0x2 0x0 >,
		           < 0x14 0x0 &gpio0 0x3 0x0 >,
		           < 0x15 0x0 &gpio0 0x2 0x0 >;    /* in zephyr/boards/nxp/lpcxpresso55s36/lpcxpresso55s36.dts:103 */
	};
};
